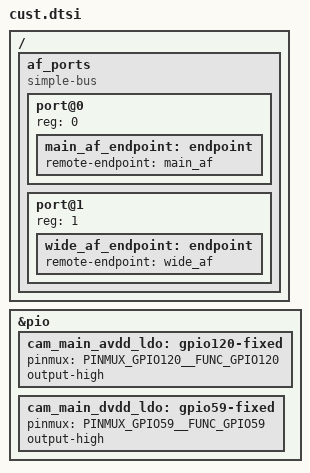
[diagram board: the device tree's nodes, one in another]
// SPDX-License-Identifier: GPL-2.0
/*
 * Copyright (c) 2022 MediaTek Inc.
 */

#include <dt-bindings/gpio/gpio.h>
#include <dt-bindings/pinctrl/mt6879-pinfunc.h>

/ {
	fragment@99 {
		target = <&pio>;
		__overlay__ {
			cam_main_avdd_ldo: gpio120-fixed {
				pinmux = <PINMUX_GPIO120__FUNC_GPIO120>;
				output-high;
			};
			
			cam_main_dvdd_ldo: gpio59-fixed {
				pinmux = <PINMUX_GPIO59__FUNC_GPIO59>;
				output-high;
			};
		};
	};

	fragment@100 {
		target-path = "/";
		__overlay__ {
			af_ports {
				compatible = "simple-bus";
				#address-cells = <1>;
				#size-cells = <0>;

				port@0 {
					reg = <0>;
					main_af_endpoint: endpoint {
						remote-endpoint = <&main_af>;
					};
				};
				port@1 {
					reg = <1>;
					wide_af_endpoint: endpoint {
						remote-endpoint = <&wide_af>;
					};
				};
			};
		};
	};
};
